# K1986VE1xI register map
Vendor: Milandr; File version: 1.0
CPU: CM1 r0p0, little endian, no MPU, no FPU, 3 interrupt priority bits
Registers are 32-bit, read-write, reset 0x0 unless marked. A register's access mark holds for its fields unless they carry their own. Offsets are from the block's base; lines under a group give offsets from that group; [hi:lo] are bit positions; {n}, {i} and the like mark numbered series; 'fields as' and 'values as' point back to an identical list; <NAME> marks a mode.

## Memory map
0x30000000 MDR_Ethernet size 0x1000 — Ethernet
0x40000000 MDR_CAN1 size 0x1000 — CAN1 interface controller registers
0x40008000 MDR_CAN2 size 0x1000 — CAN2 interface controller registers
0x40010000 MDR_USB size 0x1000 — USB interface controller registers
0x40018000 MDR_EEPROM size 0x1000 — Flash programm memory interface controller registers
0x40020000 MDR_RST_CLK size 0x1000 — RST_CLK
0x40028000 MDR_DMA size 0x1000 — DMA controller registers
0x40030000 MDR_UART1 size 0x1000 — UART1 interface controller registers
0x40038000 MDR_UART2 size 0x1000 — UART2 interface controller registers
0x40040000 MDR_SSP1 size 0x1000 — SSP1 interface controller registers
0x40048000 MDR_MIL_STD_15531 size 0x2000 — MIL_STD_1553 interface controller registers
0x40050000 MDR_MIL_STD_15532 size 0x2000 — MIL_STD_1553 interface controller registers
0x40058000 MDR_POWER size 0x1000 — POWER
0x40060000 MDR_WWDG size 0x1000 — WWDT
0x40068000 MDR_IWDG size 0x1000 — IWDT
0x40070000 MDR_TIMER1 size 0x1000 — TIMER1
0x40078000 MDR_TIMER2 size 0x1000 — TIMER2
0x40080000 MDR_TIMER3 size 0x1000 — TIMER3
0x40088000 MDR_ADC size 0x1000 — ADC
0x40090000 MDR_DAC size 0x1000 — DAC
0x40098000 MDR_TIMER4 size 0x1000 — TIMER4
0x400A0000 MDR_SSP2 size 0x1000 — SSP2
0x400A8000 MDR_PORTA size 0x1000 — PORTA
0x400B0000 MDR_PORTB size 0x1000 — PORTB
0x400B8000 MDR_PORTC size 0x1000 — PORTC
0x400C0000 MDR_PORTD size 0x1000 — PORTD
0x400C8000 MDR_PORTE size 0x1000 — PORTE
0x400D0000 MDR_ARINC429R size 0x1000 — ARINC429R
0x400D8000 MDR_BKP size 0x1000 — BACKUP
0x400E0000 MDR_ARINC429T size 0x1000 — ARINC429T
0x400E8000 MDR_PORTF size 0x1000 — PORTF
0x400F0000 MDR_EBC size 0x1000 — EBC
0x400F8000 MDR_SSP3 size 0x1000 — SSP3

## Interrupts
0 MILSTD2_IRQ (MDR_MIL_STD_15532)
1 MILSTD1_IRQ (MDR_MIL_STD_15531)
2 USB_IRQ (MDR_USB)
3 CAN1_IRQ (MDR_CAN1)
4 CAN2_IRQ (MDR_CAN2)
5 DMA_IRQ (MDR_DMA)
6 UART1_IRQ (MDR_UART1)
7 UART2_IRQ (MDR_UART2)
8 SSP1_IRQ (MDR_SSP1)
9 BUSY_IRQ (MDR_EBC)
10 ARINC429R_IRQ (MDR_ARINC429R)
11 POWER_IRQ (MDR_POWER)
12 WWDG_IRQ (MDR_WWDG)
13 Timer4_IRQ (MDR_TIMER4)
14 Timer1_IRQ (MDR_TIMER1)
15 Timer2_IRQ (MDR_TIMER2)
16 Timer3_IRQ (MDR_TIMER3)
17 ADC_IRQ (MDR_ADC)
18 ETHERNET_IRQ (MDR_Ethernet)
19 SSP3_IRQ (MDR_SSP3)
20 SSP2_IRQ (MDR_SSP2)
21 ARINC429T1_IRQ (MDR_ARINC429T)
22 ARINC429T2_IRQ (MDR_ARINC429T)
23 ARINC429T3_IRQ (MDR_ARINC429T)
24 ARINC429T4_IRQ (MDR_ARINC429T)
27 BACKUP_IRQ (MDR_BKP)
28 EXT_INT1_IRQ (MDR_PORTA)
29 EXT_INT2_IRQ (MDR_PORTA)
30 EXT_INT3_IRQ (MDR_PORTA)
31 EXT_INT4_IRQ (MDR_PORTA)

## MDR_CAN1 — CAN1 interface controller registers
Base 0x40000000
Same registers: MDR_CAN2 0x40008000
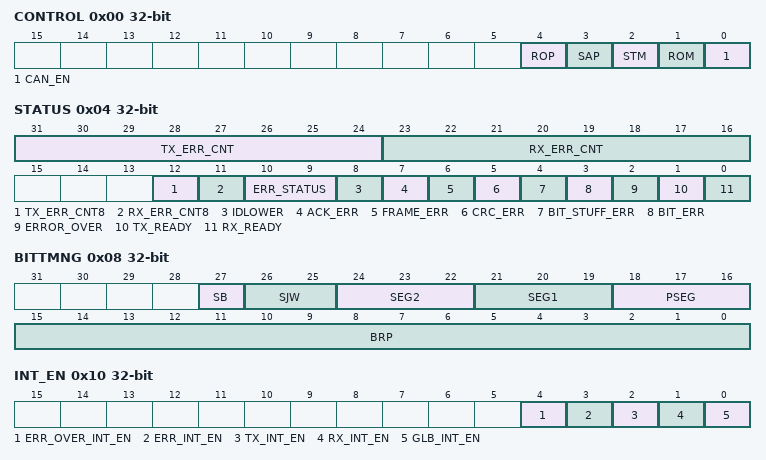
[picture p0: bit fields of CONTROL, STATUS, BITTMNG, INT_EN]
0x00 CONTROL — CAN Control Register
  [4] ROP, [3] SAP, [2] STM, [1] ROM, [0] CAN_EN
0x04 STATUS (reset mask 0xFFFF1DFF) — CAN Status Register
  [31:24] TX_ERR_CNT, [23:16] RX_ERR_CNT, [12] TX_ERR_CNT8, [11] RX_ERR_CNT8, [10:9] ERR_STATUS, [8] IDLOWER, [7] ACK_ERR, [6] FRAME_ERR, [5] CRC_ERR, [4] BIT_STUFF_ERR, [3] BIT_ERR, [2] ERROR_OVER, [1] TX_READY, [0] RX_READY
0x08 BITTMNG — CAN Bittiming Register
  [27] SB, [26:25] SJW, [24:22] SEG2, [21:19] SEG1, [18:16] PSEG, [15:0] BRP
0x10 INT_EN — CAN Interrupt enable Register
  [4] ERR_OVER_INT_EN, [3] ERR_INT_EN, [2] TX_INT_EN, [1] RX_INT_EN, [0] GLB_INT_EN
0x1C OVER
  [7:0] ERROR_MAX
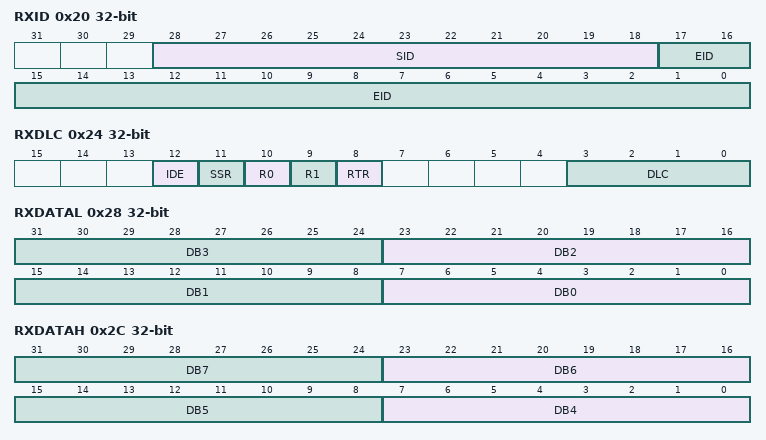
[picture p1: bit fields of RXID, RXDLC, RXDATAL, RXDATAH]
0x20 RXID — CAN Receive ID Register
  [28:18] SID, [17:0] EID
0x24 RXDLC — CAN Receive DLC Register
  [12] IDE, [11] SSR, [10] R0, [9] R1, [8] RTR, [3:0] DLC
0x28 RXDATAL — CAN Receive Data low Register
  [8n+7:8n] DB{n} (n=0..3)
0x2C RXDATAH — CAN Receive Data high Register
  [8n-25:8n-32] DB{n} (n=4..7)
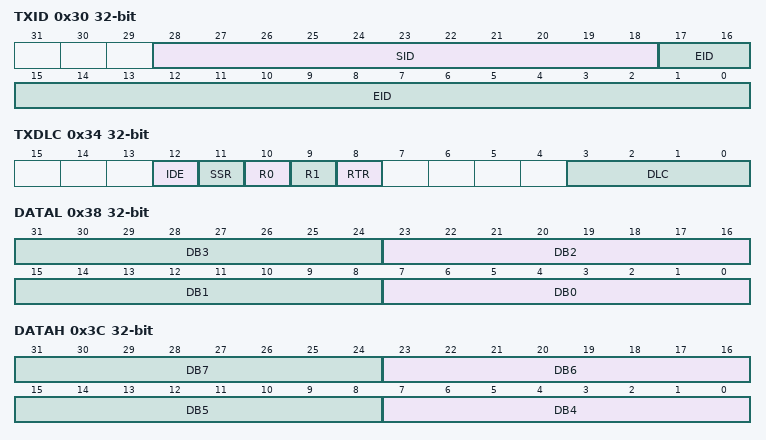
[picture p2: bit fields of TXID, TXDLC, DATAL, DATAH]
0x30 TXID — CAN Transmit ID Register
  [28:18] SID, [17:0] EID
0x34 TXDLC — CAN Transmit DLC Register
  [12] IDE, [11] SSR, [10] R0, [9] R1, [8] RTR, [3:0] DLC
0x38 DATAL — CAN Transmit Data low Register
  [8n+7:8n] DB{n} (n=0..3)
0x3C DATAH — CAN Transmit Data high Register
  [8n-25:8n-32] DB{n} (n=4..7)
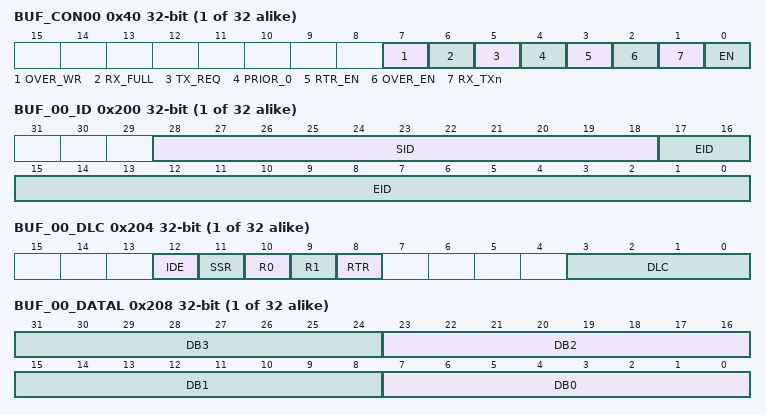
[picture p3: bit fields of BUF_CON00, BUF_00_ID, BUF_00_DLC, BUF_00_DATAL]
{0x40+4i} BUF_CON{i:02} (i=0..31) — CAN Buffer Connection Register
  [7] OVER_WR, [6] RX_FULL, [5] TX_REQ, [4] PRIOR_0, [3] RTR_EN, [2] OVER_EN, [1] RX_TXn, [0] EN
0xC0 INT_RX
0xC4 RX
0xC8 INT_TX
0xCC TX
{0x200+0x10*i} BUF_{i:02}_ID (i=0..31) — CAN Buffer ID Register
  [28:18] SID, [17:0] EID
{0x204+0x10*i} BUF_{i:02}_DLC (i=0..31) — CAN Buffer DLC Register
  [12] IDE, [11] SSR, [10] R0, [9] R1, [8] RTR, [3:0] DLC
{0x208+0x10*i} BUF_{i:02}_DATAL (i=0..31) — CAN Buffer Data low Register
  [8n+7:8n] DB{n} (n=0..3)
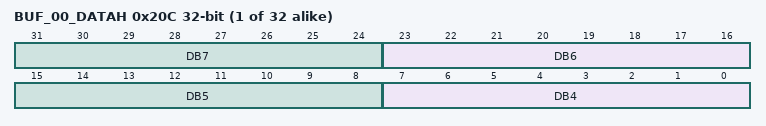
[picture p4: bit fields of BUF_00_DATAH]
{0x20C+0x10*i} BUF_{i:02}_DATAH (i=0..31) — CAN Buffer Data high Register
  [8n-25:8n-32] DB{n} (n=4..7)
{0x500+8i} BUF_FILTER{i:02}_MASK (i=0..31)
{0x504+8i} BUF_FILTER{i:02}_FILTER (i=0..31)
